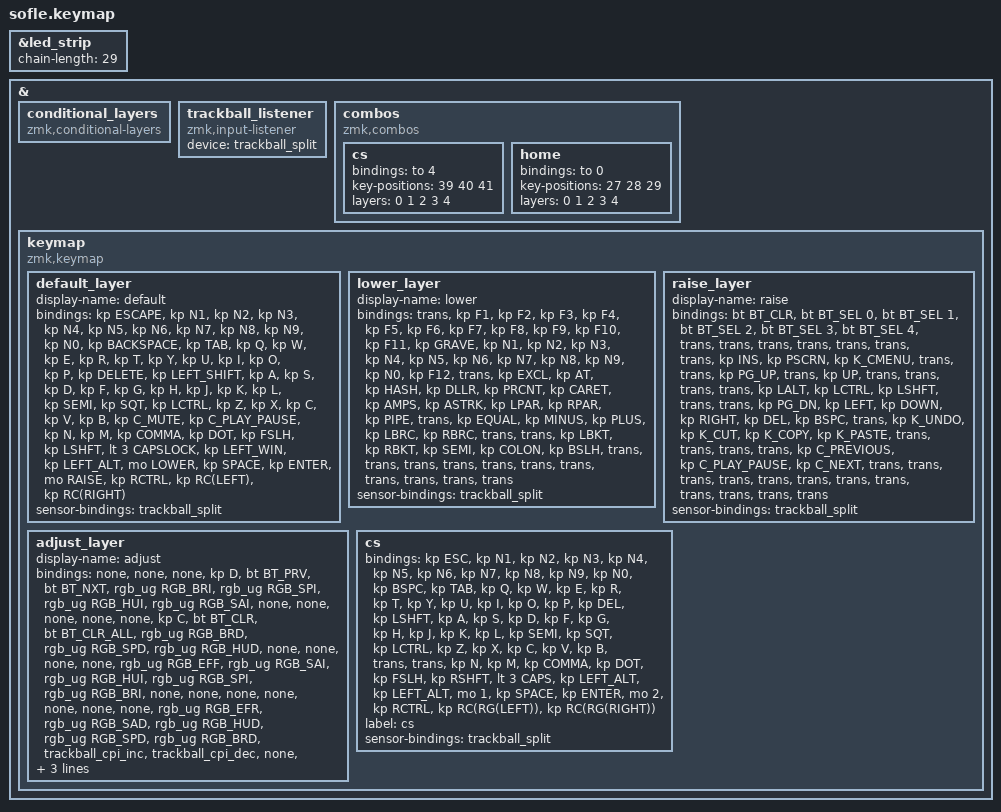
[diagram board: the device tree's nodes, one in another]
/*
 * Copyright (c) 2020 The ZMK Contributors
 *
 * SPDX-License-Identifier: MIT
 */

#include <behaviors.dtsi>
#include <dt-bindings/zmk/bt.h>
#include <dt-bindings/zmk/keys.h>
#include <dt-bindings/zmk/rgb.h>
#include <dt-bindings/zmk/mouse.h>

#define BASE 0
#define LOWER 1
#define RAISE 2
#define ADJUST 3

#define ZMK_POINTING_DEFAULT_MOVE_VAL 1500  // default: 600
#define ZMK_POINTING_DEFAULT_SCRL_VAL 20    // default: 10

&led_strip {
    chain-length = <29>; // Sofle Using All LEDs
};

& {
    conditional_layers { compatible = "zmk,conditional-layers"; };

    trackball_listener {
        compatible = "zmk,input-listener";
        device = <&trackball_split>;
    };

    combos {
        compatible = "zmk,combos";

        cs {
            bindings = <&to 4>;
            key-positions = <39 40 41>;
            layers = <0 1 2 3 4>;
        };

        home {
            bindings = <&to 0>;
            key-positions = <27 28 29>;
            layers = <0 1 2 3 4>;
        };
    };

    keymap {
        compatible = "zmk,keymap";

        default_layer {
            display-name = "default";

            bindings = <
&kp ESCAPE      &kp N1  &kp N2          &kp N3        &kp N4        &kp N5                                     &kp N6  &kp N7     &kp N8        &kp N9         &kp N0    &kp BACKSPACE
&kp TAB         &kp Q   &kp W           &kp E         &kp R         &kp T                                      &kp Y   &kp U      &kp I         &kp O          &kp P     &kp DELETE
&kp LEFT_SHIFT  &kp A   &kp S           &kp D         &kp F         &kp G                                      &kp H   &kp J      &kp K         &kp L          &kp SEMI  &kp SQT
&kp LCTRL       &kp Z   &kp X           &kp C         &kp V         &kp B      &kp C_MUTE    &kp C_PLAY_PAUSE  &kp N   &kp M      &kp COMMA     &kp DOT        &kp FSLH  &kp LSHFT
                        &lt 3 CAPSLOCK  &kp LEFT_WIN  &kp LEFT_ALT  &mo LOWER  &kp SPACE     &kp ENTER         &mo RAISE   &kp RCTRL  &kp RC(LEFT)  &kp RC(RIGHT)
            >;

            // Trackball movimento e scroll
            sensor-bindings = <&trackball_split>;
        };

        lower_layer {
            display-name = "lower";

            bindings = <
&trans     &kp F1     &kp F2     &kp F3    &kp F4    &kp F5                       &kp F6     &kp F7    &kp F8     &kp F9     &kp F10   &kp F11
&kp GRAVE  &kp N1     &kp N2     &kp N3    &kp N4    &kp N5                       &kp N6     &kp N7    &kp N8     &kp N9     &kp N0    &kp F12
&trans     &kp EXCL   &kp AT     &kp HASH  &kp DLLR  &kp PRCNT                    &kp CARET  &kp AMPS  &kp ASTRK  &kp LPAR   &kp RPAR  &kp PIPE
&trans     &kp EQUAL  &kp MINUS  &kp PLUS  &kp LBRC  &kp RBRC   &trans    &trans  &kp LBKT   &kp RBKT  &kp SEMI   &kp COLON  &kp BSLH  &trans
                      &trans     &trans    &trans    &trans     &trans    &trans  &trans     &trans    &trans     &trans
            >;

            sensor-bindings = <&trackball_split>;
        };

        raise_layer {
            display-name = "raise";

            bindings = <
&bt BT_CLR  &bt BT_SEL 0  &bt BT_SEL 1  &bt BT_SEL 2  &bt BT_SEL 3  &bt BT_SEL 4                    &trans     &trans          &trans            &trans      &trans   &trans
&trans      &kp INS       &kp PSCRN     &kp K_CMENU   &trans        &trans                          &kp PG_UP  &trans          &kp UP            &trans      &trans   &trans
&trans      &kp LALT      &kp LCTRL     &kp LSHFT     &trans        &trans                          &kp PG_DN  &kp LEFT        &kp DOWN          &kp RIGHT   &kp DEL  &kp BSPC
&trans      &kp K_UNDO    &kp K_CUT     &kp K_COPY    &kp K_PASTE   &trans        &trans    &trans  &trans     &kp C_PREVIOUS  &kp C_PLAY_PAUSE  &kp C_NEXT  &trans   &trans
                          &trans        &trans        &trans        &trans        &trans    &trans  &trans     &trans          &trans            &trans
            >;

            sensor-bindings = <&trackball_split>;
        };

        adjust_layer {
            display-name = "adjust";

            bindings = <
&none  &none            &none            &kp D            &bt BT_PRV       &bt BT_NXT                       &rgb_ug RGB_BRI  &rgb_ug RGB_SPI  &rgb_ug RGB_HUI  &rgb_ug RGB_SAI  &none  &none
&none  &none            &none            &kp C            &bt BT_CLR       &bt BT_CLR_ALL                   &rgb_ug RGB_BRD  &rgb_ug RGB_SPD  &rgb_ug RGB_HUD  &none            &none  &none
&none  &rgb_ug RGB_EFF  &rgb_ug RGB_SAI  &rgb_ug RGB_HUI  &rgb_ug RGB_SPI  &rgb_ug RGB_BRI                  &none            &none            &none            &none            &none  &none
&none  &rgb_ug RGB_EFR  &rgb_ug RGB_SAD  &rgb_ug RGB_HUD  &rgb_ug RGB_SPD  &rgb_ug RGB_BRD  &trackball_cpi_inc   &trackball_cpi_dec   &none      &none            &none            &none            &none  &none
                        &none            &none            &none            &none            &none    &none      &none            &none            &none
            >;

            sensor-bindings = <&trackball_split>;
        };

        cs {
            bindings = <
&kp ESC    &kp N1  &kp N2      &kp N3        &kp N4        &kp N5                          &kp N6  &kp N7     &kp N8            &kp N9             &kp N0    &kp BSPC
&kp TAB    &kp Q   &kp W       &kp E         &kp R         &kp T                           &kp Y   &kp U      &kp I             &kp O              &kp P     &kp DEL
&kp LSHFT  &kp A   &kp S       &kp D         &kp F         &kp G                           &kp H   &kp J      &kp K             &kp L              &kp SEMI  &kp SQT
&kp LCTRL  &kp Z   &kp X       &kp C         &kp V         &kp B   &trans       &trans     &kp N   &kp M      &kp COMMA         &kp DOT            &kp FSLH  &kp RSHFT
                   &lt 3 CAPS  &kp LEFT_ALT  &kp LEFT_ALT  &mo 1   &kp SPACE    &kp ENTER  &mo 2   &kp RCTRL  &kp RC(RG(LEFT))  &kp RC(RG(RIGHT))
            >;

            label = "cs";
            sensor-bindings = <&trackball_split>;
        };
    };
};
